# AE302F80F5582LE_CM55_HP_View register map
Vendor: Alif Semiconductor; Series: E3; File version: 1.0
CPU: CM55 r1p0, selectable endian, MPU, FPU, double-precision FPU, DSP, VTOR, 8 interrupt priority bits, 1 SAU regions
Registers are 32-bit, read-write, reset 0x0 unless marked. A register's access mark holds for its fields unless they carry their own. Offsets are from the block's base; [hi:lo] are bit positions; {n}, {i} and the like mark numbered series; 'fields as' and 'values as' point back to an identical list.

## DSI
Base 0x49032000
0x00 DSI_VERSION ro reset 0x3134312A — DSI Host Controller Version Register
  [31:0] VERSION — Module version
0x04 DSI_PWR_UP — Power-up Control Register
  [0] SHUTDOWNZ — This bit configures the controller either to power up or to reset.
    0=Reset the controller; 1=Power up the controller
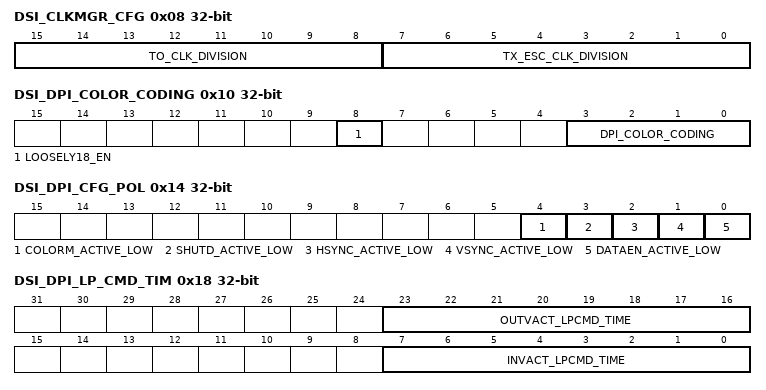
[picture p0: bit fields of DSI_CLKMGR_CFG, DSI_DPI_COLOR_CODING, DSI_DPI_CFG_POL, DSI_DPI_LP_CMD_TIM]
0x08 DSI_CLKMGR_CFG — Clock Control Register
  [15:8] TO_CLK_DIVISION — This field indicates the division factor for the Timeout clock used as the timing unit in the configuration of high-speed to low-power and low-power to high-speed transition error.
  [7:0] TX_ESC_CLK_DIVISION — This field indicates the division factor for the TX Escape clock source (LANEBYTECLK). The values 0 and 1 stop the TXCLKESC generation.
0x0C DSI_DPI_VCID — VC ID Configuration Register
  [1:0] DPI_VCID — This field configures the DPI Virtual Channel ID that is indexed to the Video mode packets.
0x10 DSI_DPI_COLOR_CODING — DPI Color Coding Register
  [8] LOOSELY18_EN — When set to 1, this bit activates loosely packed variant to 18-bit configurations.
  [3:0] DPI_COLOR_CODING — This field configures the DPI color for Video mode coding as follows:
    1=16-bit configuration 2; 4=18-bit configuration 2; 5=24-bit
0x14 DSI_DPI_CFG_POL — DPI Polarity Configuration Register
  [4] COLORM_ACTIVE_LOW — When set to 1, this bit configures the color mode pin (DPICOLORM) as active-low.
  [3] SHUTD_ACTIVE_LOW — When set to 1, this bit configures the shutdown pin (DPISHUTDN) as active-low.
  [2] HSYNC_ACTIVE_LOW — When set to 1, this bit configures the horizontal synchronism pin (DPIHSYNC) as active-low.
  [1] VSYNC_ACTIVE_LOW — When set to 1, this bit configures the vertical synchronism pin (DPIVSYNC) as active-low.
  [0] DATAEN_ACTIVE_LOW — When set to 1, this bit configures the data enable pin (DPIDATAEN) as active-low.
0x18 DSI_DPI_LP_CMD_TIM — DPI Low-Power Mode Configuration Register
  [23:16] OUTVACT_LPCMD_TIME — This field is used for the transmission of commands in low-power mode. It defines the size, in bytes, of the largest packet that can fit in a line during the VSA, VBP, and VFP regions.
  [7:0] INVACT_LPCMD_TIME — This field is used for the transmission of commands in low-power mode. It defines the size, in bytes, of the largest packet that can fit in a line during the VACT region.
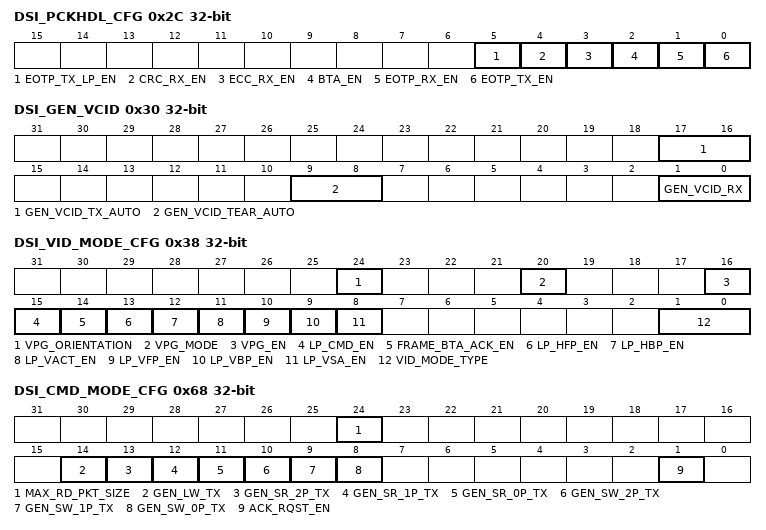
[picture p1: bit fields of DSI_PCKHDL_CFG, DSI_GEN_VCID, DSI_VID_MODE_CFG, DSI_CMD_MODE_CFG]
0x2C DSI_PCKHDL_CFG — Protocol Configuration Register
  [5] EOTP_TX_LP_EN — When set to 1, this bit enables the EoTp transmission in low-power.
  [4] CRC_RX_EN — When set to 1, this bit enables the CRC reception and error reporting.
  [3] ECC_RX_EN — When set to 1, this bit enables the ECC reception, error correction, and reporting.
  [2] BTA_EN — When set to 1, this bit enables the Bus Turn-Around (BTA) request.
  [1] EOTP_RX_EN — When set to 1, this bit enables the EoTp reception.
  [0] EOTP_TX_EN — When set to 1, this bit enables the EoTp transmission in high-speed.
0x30 DSI_GEN_VCID — Generic VC ID Configuration Register
  [17:16] GEN_VCID_TX_AUTO — This field indicates the Generic interface virtual channel identification where generic packet is automatically generated and transmitted.
  [9:8] GEN_VCID_TEAR_AUTO — This field indicates the virtual channel identification for tear effect by hardware
  [1:0] GEN_VCID_RX — This field indicates the Generic interface read-back virtual channel identification.
0x34 DSI_MODE_CFG reset 0x1 — Mode Configuration Register
  [0] CMD_VIDEO_MODE — This bit configures the operation mode:
    0=Video mode; 1=Command mode. Not supported by the DSI controller in this device.
0x38 DSI_VID_MODE_CFG — Video Mode Configuration Register
  [24] VPG_ORIENTATION — This field indicates the color bar orientation as follows:
    0=Vertical mode; 1=Horizontal mode
  [20] VPG_MODE — This field is to select the pattern:
    0=Horizontal or vertical; 1=Vertical only
  [16] VPG_EN — When set to 1, this bit enables the video mode pattern generator.
  [15] LP_CMD_EN — When set to 1, this bit enables the command transmission only in low-power mode.
  [14] FRAME_BTA_ACK_EN — When set to 1, this bit enables the request for an acknowledge response at the end of a frame.
  [13] LP_HFP_EN — When set to 1, this bit enables the return to low-power inside the HFP period when timing allows.
  [12] LP_HBP_EN — When set to 1, this bit enables the return to low-power inside the HBP period when timing allows.
  [11] LP_VACT_EN — When set to 1, this bit enables the return to low-power inside the VACT period when timing allows.
  [10] LP_VFP_EN — When set to 1, this bit enables the return to low-power inside the VFP period when timing allows.
  [9] LP_VBP_EN — When set to 1, this bit enables the return to low-power inside the VBP period when timing allows.
  [8] LP_VSA_EN — When set to 1, this bit enables the return to low-power inside the VSA period when timing allows.
  [1:0] VID_MODE_TYPE — This field indicates the video mode transmission type as follows:
    0=Non-Burst with sync pulses; 1=Non-Burst with sync events; 2=Burst mode; 3=Burst mode
0x3C DSI_VID_PKT_SIZE — Video Packet Size Register
  [13:0] VID_PKT_SIZE — This field configures the number of pixels in a single video packet.
0x40 DSI_VID_NUM_CHUNKS — Video Chunks Configuration Register
  [12:0] VID_NUM_CHUNKS — This register configures the number of chunks to be transmitted during a Line period (a chunk is pair made of a video packet and a null packet). If set to 0 or 1, video line is still transmitted in a single packet. If set to 1 that packet is part of a chunk, meaning that a null packet follows it (if DSI_VID_NULL_SIZE > 0). Otherwise, multiple chunks are used to transmit each video line.
0x44 DSI_VID_NULL_SIZE — Video Null Packet Configuration Register
  [12:0] VID_NULL_SIZE — This register configures the number of bytes inside a null packet. Setting to 0 disables null packets.
0x48 DSI_VID_HSA_TIME — Video HSA Configuration Register
  [11:0] VID_HSA_TIME — This field configures the Horizontal Synchronism Active period in LANEBYTECLK cycles.
0x4C DSI_VID_HBP_TIME — Video HBP Configuration Register
  [11:0] VID_HBP_TIME — This field configures the HBP period in LANEBYTECLK cycles.
0x50 DSI_VID_HLINE_TIME — Video Line Configuration Register
  [14:0] VID_HLINE_TIME — This field configures the size of the total line time (HSA + HBP + HACT + HFP) counted in LANEBYTECLK cycles.
0x54 DSI_VID_VSA_LINES — Video VSA Configuration Register
  [9:0] VSA_LINES — This field configures the VSA period measured in number of horizontal lines.
0x58 DSI_VID_VBP_LINES — Video VBP Configuration Register
  [9:0] VBP_LINES — This field configures the VBP period measured in number of horizontal lines.
0x5C DSI_VID_VFP_LINES — Video VFP Configuration Register
  [9:0] VFP_LINES — This field configures the VFP period measured in number of horizontal lines.
0x60 DSI_VID_VACTIVE_LINES — Video VA Configuration Register
  [13:0] V_ACTIVE_LINES — This field configures the VA period measured in number of horizontal lines.
0x68 DSI_CMD_MODE_CFG — Generic Packet Command Configuration Register
  [24] MAX_RD_PKT_SIZE — This bit configures the maximum read packet size command transmission type:
    0=Transition type is high-speed; 1=Transition type is low-power
  [14] GEN_LW_TX — This bit configures the Generic long write packet command transmission type:
    values as MAX_RD_PKT_SIZE
  [13] GEN_SR_2P_TX — This bit configures the Generic short read packet with two parameters command transmission type:
    values as MAX_RD_PKT_SIZE
  [12] GEN_SR_1P_TX — This bit configures the Generic short read packet with one parameter command transmission type:
    values as MAX_RD_PKT_SIZE
  [11] GEN_SR_0P_TX — This bit configures the Generic short read packet with zero parameter command transmission type:
    values as MAX_RD_PKT_SIZE
  [10] GEN_SW_2P_TX — This bit configures the Generic short write packet with two parameters command transmission type:
    values as MAX_RD_PKT_SIZE
  [9] GEN_SW_1P_TX — This bit configures the Generic short write packet with one parameter command transmission type:
    values as MAX_RD_PKT_SIZE
  [8] GEN_SW_0P_TX — This bit configures the Generic short write packet with zero parameter command transmission type:
    values as MAX_RD_PKT_SIZE
  [1] ACK_RQST_EN — When set to 1, this bit enables the acknowledge request after each packet transmission.
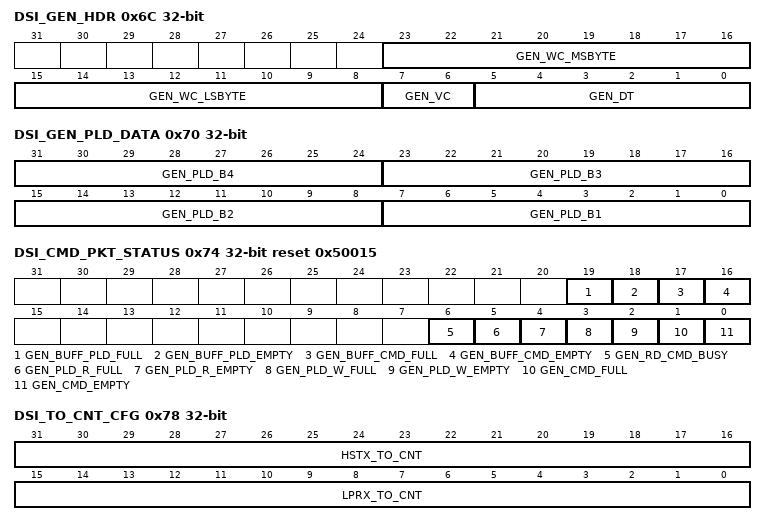
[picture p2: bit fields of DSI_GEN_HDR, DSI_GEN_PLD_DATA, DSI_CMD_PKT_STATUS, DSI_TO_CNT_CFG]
0x6C DSI_GEN_HDR — Generic Header Configuration Register
  [23:16] GEN_WC_MSBYTE — This field configures the most significant byte of the header packet's word count for long packets or data 1 for short packets.
  [15:8] GEN_WC_LSBYTE — This field configures the least significant byte of the header packet's Word count for long packets or data 0 for short packets.
  [7:6] GEN_VC — This field configures the Virtual Channel ID of the header packet.
  [5:0] GEN_DT — This field configures the packet Data Type of the header packet.
0x70 DSI_GEN_PLD_DATA — Generic Payload Data Register
  [8n-1:8n-8] GEN_PLD_B{n} (n=1..4) — This field indicates byte {n} of the packet payload.
0x74 DSI_CMD_PKT_STATUS ro reset 0x50015 — Generic Packet Status Register
  [19] GEN_BUFF_PLD_FULL — This bit indicates the full status of the generic payload internal buffer.
  [18] GEN_BUFF_PLD_EMPTY — This bit indicates the empty status of the generic payload internal buffer.
  [17] GEN_BUFF_CMD_FULL — This bit indicates the full status of the generic command internal buffer.
  [16] GEN_BUFF_CMD_EMPTY — This bit indicates the empty status of the generic command internal buffer.
  [6] GEN_RD_CMD_BUSY — This bit is set when a read command is issued and cleared when the entire response is stored in the FIFO for Generic interface.
  [5] GEN_PLD_R_FULL — This bit indicates the full status of the generic read payload FIFO.
  [4] GEN_PLD_R_EMPTY — This bit indicates the empty status of the generic read payload FIFO.
  [3] GEN_PLD_W_FULL — This bit indicates the full status of the generic write payload FIFO.
  [2] GEN_PLD_W_EMPTY — This bit indicates the empty status of the generic write payload FIFO.
  [1] GEN_CMD_FULL — This bit indicates the full status of the generic command FIFO.
  [0] GEN_CMD_EMPTY — This bit indicates the empty status of the generic command FIFO.
0x78 DSI_TO_CNT_CFG — Timeout Counter Configuration Register
  [31:16] HSTX_TO_CNT — This field configures the timeout counter that triggers a high-speed transmission timeout contention detection (measured in DSI_CLKMGR_CFG[TO_CLK_DIVISION] cycles). If using non-burst mode and there is not sufficient time to switch from high-speed to low-power and back in the period which is from one line data finishing to the next line sync start, the DSI link returns low-power state once per frame, then the DSI_CLKMGR_CFG[TO_CLK_DIVISION] and HSTX_TO_CNT fields should be configured to satisfy the following formula: HSTX_TO_CNT x LANEBYTECLK_period x TO_CLK_DIVISION >= the time of one FRAME data transmission x (1 + 10%) In burst mode, RGB pixel packets are time-compressed, leaving more time during a scan line. So if in burst mode and there is sufficient time to switch from high-speed to low-power and back in the period of time from one line data finishing to the next line sync start, the DSI link can return low-power mode and back in this time interval to save power. If this case, the DSI_CLKMGR_CFG[TO_CLK_DIVISION] and HSTX_TO_CNT fields should be configured to satisfy the following formula: HSTX_TO_CNT x LANEBYTECLK_period x TO_CLK_DIVISION >= the time of one LINE data transmission x (1 + 10%)
  [15:0] LPRX_TO_CNT — This field configures the timeout counter that triggers a low-power reception timeout contention detection (measured in DSI_CLKMGR_CFG[TO_CLK_DIVISION] cycles).
0x7C DSI_HS_RD_TO_CNT — HS Read Timeout Configuration Register
  [15:0] HS_RD_TO_CNT — This field sets a period for which DSI controller keeps the link still, after sending a high-speed Read operation. This period is measured in cycles of LANEBYTECLK, starts to count when the D-PHY enters stop state and causes no interrupts.
0x80 DSI_LP_RD_TO_CNT — LP Read Timeout Configuration Register
  [15:0] LP_RD_TO_CNT — This field sets a period for which DSI controller keeps the link still, after sending a low-power Read operation. This period is measured in cycles of LANEBYTECLK, starts to count when the D-PHY enters stop state and causes no interrupts.
0x84 DSI_HS_WR_TO_CNT — HS Write Timeout Configuration Register
  [15:0] HS_WR_TO_CNT — This field sets a period for which DSI controller keeps the link still, after sending a high-speed Write operation. This period is measured in cycles of LANEBYTECLK, starts to count when the D-PHY enters stop state and causes no interrupts.
0x88 DSI_LP_WR_TO_CNT — LP Write Timeout Configuration Register
  [15:0] LP_WR_TO_CNT — This field sets a period for which DSI controller keeps the link still, after sending a low-power Write operation. This period is measured in cycles of LANEBYTECLK, starts to count when the D-PHY enters stop state and causes no interrupts.
0x8C DSI_BTA_TO_CNT — BTA Timeout Configuration Register
  [15:0] BTA_TO_CNT — This field sets a period for which DSI controller keeps the link still, after completing a BTA. This period is measured in cycles of LANEBYTECLK, starts to count when the D-PHY enters Stop state and causes no interrupts.
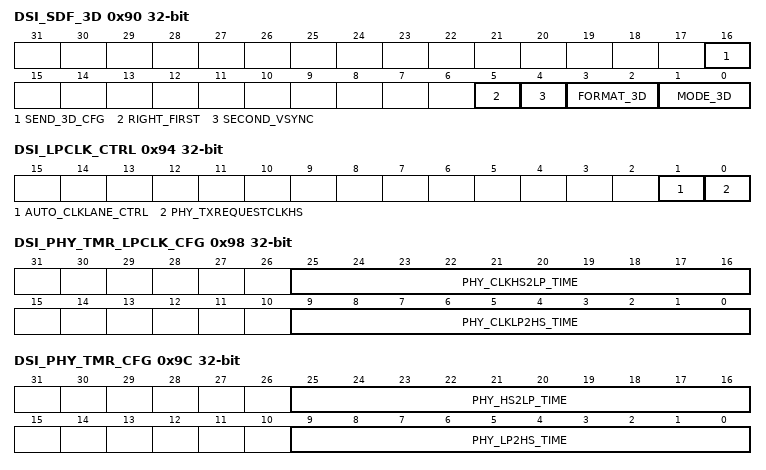
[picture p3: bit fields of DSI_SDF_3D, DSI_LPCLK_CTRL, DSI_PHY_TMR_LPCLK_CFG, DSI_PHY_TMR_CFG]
0x90 DSI_SDF_3D — 3D Control Register
  [16] SEND_3D_CFG — When set, causes the next VSS packet to include 3D control payload in every VSS packet.
  [5] RIGHT_FIRST — This bit defines the left/right order:
    0=Left eye is sent first, then right eye; 1=Right eye data is sent first, then left eye
  [4] SECOND_VSYNC — This field defines whether there is a second VSYNC pulse between Left and Right Images, when 3D Image Format is Frame-based:
    0=No sync pulses between left and right data; 1=Sync pulse HSYNC, VSYNC, blanking between left and right data
  [3:2] FORMAT_3D — This field defines 3D Image Format:
    0=Alternating lines of left and right data; 1=Alternating frames of left and right data; 2=Alternating pixels of left and right data
  [1:0] MODE_3D — This field defines 3D Mode On/Off and Display Orientation:
    0=3D Mode Off , 2D Mode On; 1=3D Mode On, Portrait Orientation; 2=3D Mode On, Landscape Orientation
0x94 DSI_LPCLK_CTRL — Clock Lane Power Control Register
  [1] AUTO_CLKLANE_CTRL — This bit enables the automatic mechanism to stop providing clock in the clock lane when time allows.
  [0] PHY_TXREQUESTCLKHS — This bit controls the D-PHY PPI TXREQUESTCLKHS signal.
0x98 DSI_PHY_TMR_LPCLK_CFG — Clock Lane Timer Configuration Register
  [25:16] PHY_CLKHS2LP_TIME — This field configures the maximum time that the D-PHY clock lane takes to go from high-speed to low-power transmission measured in LANEBYTECLK cycles.
  [9:0] PHY_CLKLP2HS_TIME — This field configures the maximum time that the D-PHY clock lane takes to go from low-power to high-speed transmission measured in LANEBYTECLK cycles.
0x9C DSI_PHY_TMR_CFG — Data Lane Timer Configuration Register
  [25:16] PHY_HS2LP_TIME — This field configures the maximum time that the D-PHY data lanes take to go from high-speed to low-power transmission measured in LANEBYTECLK cycles.
  [9:0] PHY_LP2HS_TIME — This field configures the maximum time that the D-PHY data lanes take to go from low-power to high-speed transmission measured in LANEBYTECLK cycles.
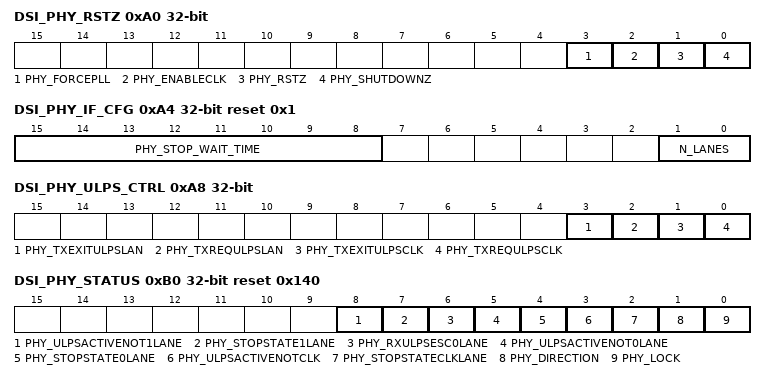
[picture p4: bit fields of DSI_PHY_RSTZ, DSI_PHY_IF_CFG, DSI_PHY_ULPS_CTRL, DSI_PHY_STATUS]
0xA0 DSI_PHY_RSTZ — PHY Control Register
  [3] PHY_FORCEPLL — When the D-PHY is in ULPS, this bit enables the D-PHY PLL.
  [2] PHY_ENABLECLK — When set to 1, this bit enables the D-PHY Clock Lane module.
  [1] PHY_RSTZ — When set to 0, this bit places the digital section of the D-PHY in the reset state.
  [0] PHY_SHUTDOWNZ — When set to 0, this bit places the all D-PHY sub-blocks in power-down state.
0xA4 DSI_PHY_IF_CFG reset 0x1 — PHY Configuration Register
  [15:8] PHY_STOP_WAIT_TIME — This field configures the minimum time PHY needs to stay in Stop state before requesting an high-speed transmission.
  [1:0] N_LANES — This field configures the number of active data lanes:
    0=Data lane 0; 1=Data lanes 0 and 1
0xA8 DSI_PHY_ULPS_CTRL — PHY ULPS Control Register
  [3] PHY_TXEXITULPSLAN — ULPS mode Exit on all active data lanes.
  [2] PHY_TXREQULPSLAN — ULPS mode Request on all active data lanes.
  [1] PHY_TXEXITULPSCLK — ULPS mode Exit on clock lane.
  [0] PHY_TXREQULPSCLK — ULPS mode Request on clock lane.
0xAC DSI_PHY_TX_TRIGGERS — PHY TX Trigger Configuration Register
  [3:0] PHY_TX_TRIGGERS — This field controls the trigger transmissions.
0xB0 DSI_PHY_STATUS ro reset 0x140 — PHY Status Register
  [8] PHY_ULPSACTIVENOT1LANE — This bit indicates the status of ULPSACTIVENOT1LANE D-PHY signal.
  [7] PHY_STOPSTATE1LANE — This bit indicates the status of PHYSTOPSTATE1LANE D-PHY signal.
  [6] PHY_RXULPSESC0LANE — This bit indicates the status of RXULPSESC0LANE D-PHY signal.
  [5] PHY_ULPSACTIVENOT0LANE — This bit indicates the status of ULPSACTIVENOT0LANE D-PHY signal.
  [4] PHY_STOPSTATE0LANE — This bit indicates the status of PHYSTOPSTATE0LANE D-PHY signal.
  [3] PHY_ULPSACTIVENOTCLK — This bit indicates the status of PHYULPSACTIVENOTCLK D-PHY signal.
  [2] PHY_STOPSTATECLKLANE — This bit indicates the status of PHYSTOPSTATECLKLANE D-PHY signal.
  [1] PHY_DIRECTION — This bit indicates the status of PHYDIRECTION D-PHY signal.
  [0] PHY_LOCK — This bit indicates the status of PHYLOCK D-PHY signal.
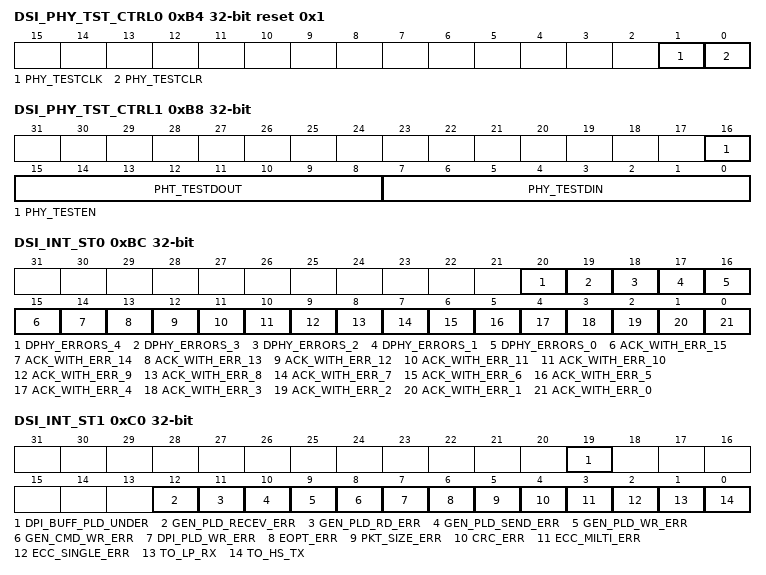
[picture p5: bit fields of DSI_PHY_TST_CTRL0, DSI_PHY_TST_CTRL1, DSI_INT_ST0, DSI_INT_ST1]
0xB4 DSI_PHY_TST_CTRL0 reset 0x1 — PHY Test Interface Control Register 0
  [1] PHY_TESTCLK — This bit is used to clock the TESTDIN bus into the D-PHY.
  [0] PHY_TESTCLR — PHY test interface clear (active-high).
0xB8 DSI_PHY_TST_CTRL1 — PHY Test Interface Control Register 1
  [16] PHY_TESTEN — PHY test interface operation selector:
    0=The data write operation is set on the rising edge of the TESTCLK signal; 1=The address write operation is set on the falling edge of the TESTCLK signal
  [15:8] PHT_TESTDOUT ro — PHY output 8-bit data bus for read-back and internal probing functionalities.
  [7:0] PHY_TESTDIN — PHY test interface input 8-bit data bus for internal register programming and test functionalities access.
0xBC DSI_INT_ST0 ro — Interrupt Status Register 0
  [20] DPHY_ERRORS_4 — This bit indicates LP1 contention error ErrContentionLP1 from Lane 0.
  [19] DPHY_ERRORS_3 — This bit indicates LP0 contention error ErrContentionLP0 from Lane 0.
  [18] DPHY_ERRORS_2 — This bit indicates control error ErrControl from Lane 0.
  [17] DPHY_ERRORS_1 — This bit indicates ErrSyncEsc low-power data transmission synchronization error from Lane 0.
  [16] DPHY_ERRORS_0 — This bit indicates ErrEsc escape entry error from Lane 0.
  [15] ACK_WITH_ERR_15 — This bit retrieves the DSI protocol violation from the Acknowledge error report.
  [14] ACK_WITH_ERR_14 — This bit retrieves the reserved (specific to device) from the Acknowledge error report.
  [13] ACK_WITH_ERR_13 — This bit retrieves the invalid transmission length from the Acknowledge error report.
  [12] ACK_WITH_ERR_12 — This bit retrieves the DSI VC ID Invalid from the Acknowledge error report.
  [11] ACK_WITH_ERR_11 — This bit retrieves the not recognized DSI data type from the Acknowledge error report.
  [10] ACK_WITH_ERR_10 — This bit retrieves the checksum error (long packet only) from the Acknowledge error report.
  [9] ACK_WITH_ERR_9 — This bit retrieves the ECC error, multi-bit (detected, not corrected) from the Acknowledge error report.
  [8] ACK_WITH_ERR_8 — This bit retrieves the ECC error, single-bit (detected and corrected) from the Acknowledge error report.
  [7] ACK_WITH_ERR_7 — This bit retrieves the reserved (specific to device) from the acknowledge error report.
  [6] ACK_WITH_ERR_6 — This bit retrieves the False Control error from the Acknowledge error report.
  [5] ACK_WITH_ERR_5 — This bit retrieves the Peripheral Timeout error from the Acknowledge error report.
  [4] ACK_WITH_ERR_4 — This bit retrieves the low-power Transmit Sync error from the Acknowledge error report.
  [3] ACK_WITH_ERR_3 — This bit retrieves the Escape Mode Entry Command error from the Acknowledge error report.
  [2] ACK_WITH_ERR_2 — This bit retrieves the EoT Sync error from the Acknowledge error report.
  [1] ACK_WITH_ERR_1 — This bit retrieves the SoT Sync error from the Acknowledge error report.
  [0] ACK_WITH_ERR_0 — This bit retrieves the SoT error from the Acknowledge error report.
0xC0 DSI_INT_ST1 ro — Interrupt Status Register 1
  [19] DPI_BUFF_PLD_UNDER — This bit indicates that an underflow has occurred when reading payload to build DSI packet for video mode.
  [12] GEN_PLD_RECEV_ERR — This bit indicates that during a generic interface packet read back, the payload FIFO becomes full and the received data is corrupted.
  [11] GEN_PLD_RD_ERR — This bit indicates that during a DCS read data, the payload FIFO becomes empty and the data sent to the interface is corrupted.
  [10] GEN_PLD_SEND_ERR — This bit indicates that during a Generic interface packet build, the payload FIFO becomes empty and corrupt data is sent.
  [9] GEN_PLD_WR_ERR — This bit indicates that the system tried to write a payload data through the Generic interface and the FIFO is full. Therefore, the payload is not written.
  [8] GEN_CMD_WR_ERR — This bit indicates that the system tried to write a command through the Generic interface and the FIFO is full. Therefore, the command is not written.
  [7] DPI_PLD_WR_ERR — This bit indicates that during a DPI pixel line storage, the payload FIFO becomes full and the data stored is corrupted.
  [6] EOPT_ERR — This bit indicates that the EoTp packet has not been received at the end of the incoming peripheral transmission.
  [5] PKT_SIZE_ERR — This bit indicates that the packet size error has been detected during the packet reception.
  [4] CRC_ERR — This bit indicates that the CRC error has been detected in the received packet payload.
  [3] ECC_MILTI_ERR — This bit indicates that the ECC multiple error has been detected in a received packet.
  [2] ECC_SINGLE_ERR — This bit indicates that the ECC single error has been detected and corrected in a received packet.
  [1] TO_LP_RX — This bit indicates that the low-power reception timeout counter reached the end and contention has been detected.
  [0] TO_HS_TX — This bit indicates that the high-speed transmission timeout counter reached the end and contention has been detected.
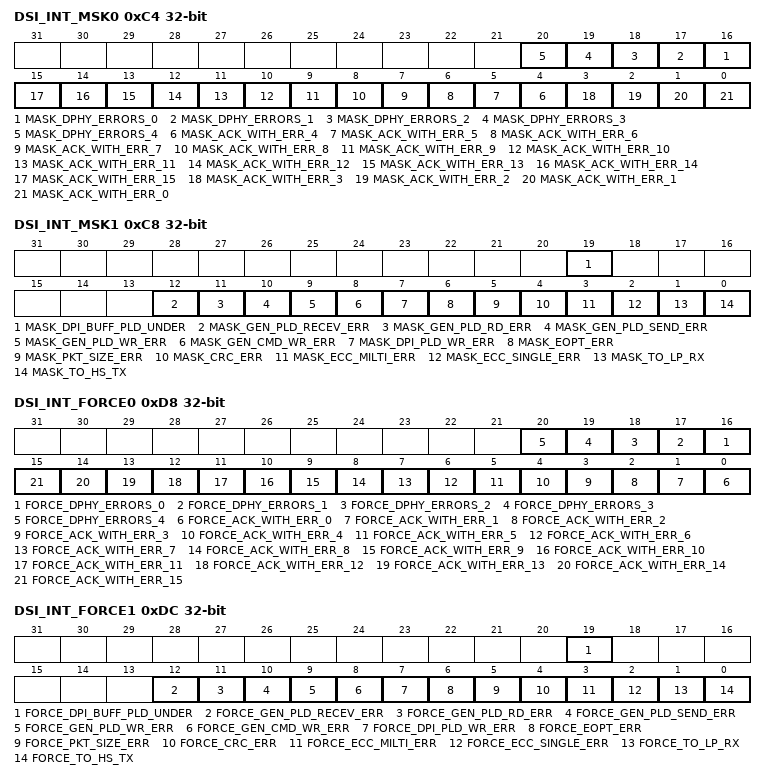
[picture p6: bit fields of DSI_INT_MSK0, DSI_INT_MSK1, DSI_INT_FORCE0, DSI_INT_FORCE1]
0xC4 DSI_INT_MSK0 — Interrupt Mask Register 0
  [n+16] MASK_DPHY_ERRORS_{n} (n=0..4) — Mask for DPHY_ERRORS_{n}.
  [n] MASK_ACK_WITH_ERR_{n} (n=4..15) — Mask for ACK_WITH_ERR_{n}.
  [3] MASK_ACK_WITH_ERR_3 — Mask for ACK_WITH_ERR_3
  [2] MASK_ACK_WITH_ERR_2 — Mask for ACK_WITH_ERR_2
  [1] MASK_ACK_WITH_ERR_1 — Mask for ACK_WITH_ERR_1.
  [0] MASK_ACK_WITH_ERR_0 — Mask for ACK_WITH_ERR_0.
0xC8 DSI_INT_MSK1 — Interrupt Mask Register 1
  [19] MASK_DPI_BUFF_PLD_UNDER — Mask for DPI_BUFF_PLD_UNDER.
  [12] MASK_GEN_PLD_RECEV_ERR — Mask for GEN_PLD_RECEV_ERR.
  [11] MASK_GEN_PLD_RD_ERR — Mask for GEN_PLD_RD_ERR.
  [10] MASK_GEN_PLD_SEND_ERR — Mask for GEN_PLD_SEND_ERR.
  [9] MASK_GEN_PLD_WR_ERR — Mask for GEN_PLD_WR_ERR.
  [8] MASK_GEN_CMD_WR_ERR — Mask for GEN_CMD_WR_ERR.
  [7] MASK_DPI_PLD_WR_ERR — Mask for DPI_PLD_WR_ERR.
  [6] MASK_EOPT_ERR — Mask for EOPT_ERR.
  [5] MASK_PKT_SIZE_ERR — Mask for PKT_SIZE_ERR.
  [4] MASK_CRC_ERR — Mask for CRC_ERR.
  [3] MASK_ECC_MILTI_ERR — Mask for ECC_MILTI_ERR.
  [2] MASK_ECC_SINGLE_ERR — Mask for ECC_SINGLE_ERR.
  [1] MASK_TO_LP_RX — Mask for TO_LP_RX.
  [0] MASK_TO_HS_TX — Mask for TO_HS_TX.
0xCC DSI_PHY_CAL — PHY skew calibration control
  [0] TXSKEWCALHS — High-speed skew calibration is started when this field is set high (assuming that PHY is in Stop state).
0xD8 DSI_INT_FORCE0 — Force Interrupt Register 0
  [n+16] FORCE_DPHY_ERRORS_{n} (n=0..4), [n] FORCE_ACK_WITH_ERR_{n} (n=0..15)
0xDC DSI_INT_FORCE1 — Force Interrupt Register 1
  [19] FORCE_DPI_BUFF_PLD_UNDER — Force for DPI_BUFF_PLD_UNDER.
  [12] FORCE_GEN_PLD_RECEV_ERR
  [11] FORCE_GEN_PLD_RD_ERR
  [10] FORCE_GEN_PLD_SEND_ERR
  [9] FORCE_GEN_PLD_WR_ERR
  [8] FORCE_GEN_CMD_WR_ERR
  [7] FORCE_DPI_PLD_WR_ERR
  [6] FORCE_EOPT_ERR
  [5] FORCE_PKT_SIZE_ERR
  [4] FORCE_CRC_ERR
  [3] FORCE_ECC_MILTI_ERR
  [2] FORCE_ECC_SINGLE_ERR
  [1] FORCE_TO_LP_RX
  [0] FORCE_TO_HS_TX
0xF4 DSI_PHY_TMR_RD_CFG — Data Lane Timer Read Configuration Register
  [14:0] MAX_RD_TIME — This field configures the maximum time required to perform a read command in LANEBYTECLK cycles. This register can only be modified when no read command is in progress.
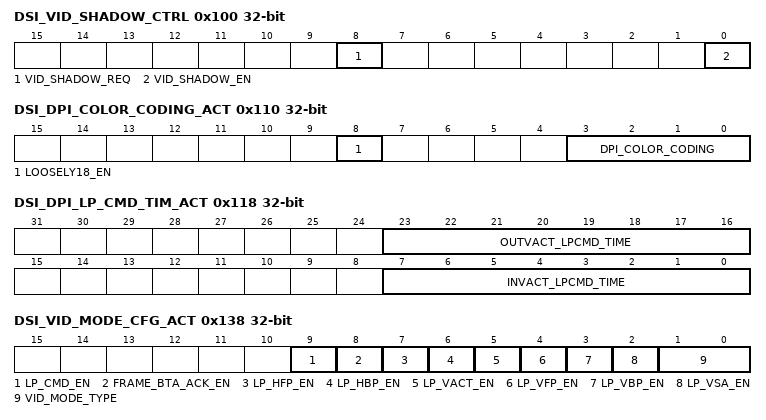
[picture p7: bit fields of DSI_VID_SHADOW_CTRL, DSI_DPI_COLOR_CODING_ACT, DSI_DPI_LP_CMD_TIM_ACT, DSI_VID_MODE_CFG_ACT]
0x100 DSI_VID_SHADOW_CTRL — Video Shadow Control Register
  [8] VID_SHADOW_REQ — When set to 1, this bit requests that the DPI registers are copied to the auxiliary registers. When the request is completed this bit is auto cleared.
  [0] VID_SHADOW_EN — When set to 1, DPI receives the active configuration from the auxiliary registers. When the feature is set at the same time than VID_SHADOW_REQ the auxiliary registers are automatically updated.
0x10C DSI_DPI_VCID_ACT ro — Current VC ID Register
  [1:0] DPI_VCID — This field specifies the DPI Virtual Channel ID that is indexed to the Video mode packets.
0x110 DSI_DPI_COLOR_CODING_ACT ro — Current Color Coding Register
  [8] LOOSELY18_EN — When 1, this bit activates loosely packed variant to 18-bit configurations.
  [3:0] DPI_COLOR_CODING — This field configures the DPI color for Video Mode/eDPI Command Mode coding as follows:
    1=16-bit configuration 2; 4=18-bit configuration 2; 5=24-bit
0x118 DSI_DPI_LP_CMD_TIM_ACT ro — Low-Power Mode Current Configuration Register
  [23:16] OUTVACT_LPCMD_TIME — This field is used for the transmission of commands in low-power mode. It specifies the size, in bytes, of the largest packet that can fit in a line during the VSA, VBP, and VFP regions.
  [7:0] INVACT_LPCMD_TIME — This field is used for the transmission of commands in low-power mode. It specifies the size, in bytes, of the largest packet that can fit in a line during the VACT region.
0x138 DSI_VID_MODE_CFG_ACT ro — Video Mode Current Configuration Register
  [9] LP_CMD_EN — When 1, this bit enables the command transmission only in low-power mode.
  [8] FRAME_BTA_ACK_EN — When 1, this bit enables the request for an acknowledge response at the end of a frame.
  [7] LP_HFP_EN — When 1, this bit enables the return to low-power inside the HFP period when timing allows.
  [6] LP_HBP_EN — When 1, this bit enables the return to low-power inside the HBP period when timing allows.
  [5] LP_VACT_EN — When 1, this bit enables the return to low-power inside the VACT period when timing allows.
  [4] LP_VFP_EN — When 1, this bit enables the return to low-power inside the VFP period when timing allows.
  [3] LP_VBP_EN — When 1, this bit enables the return to low-power inside the VBP period when timing allows.
  [2] LP_VSA_EN — When 1, this bit enables the return to low-power inside the VSA period when timing allows.
  [1:0] VID_MODE_TYPE — This field specifies the Video mode transmission type as follows:
    values as DSI_VID_MODE_CFG.VID_MODE_TYPE
0x13C DSI_VID_PKT_SIZE_ACT ro — Video Packet Size Current Configuration Register
  [13:0] VID_PKT_SIZE — This field specifies the number of pixels in a single video packet.
0x140 DSI_VID_NUM_CHUNKS_ACT ro — Video Chunks Current Configuration Register
  [12:0] VID_NUM_CHUNKS — This register specifies the number of chunks to be transmitted during a Line period (a chunk is pair made of a video packet and a null packet). If set to 0 or 1, video line is still transmitted in a single packet. If set to 1 that packet is part of a chunk, meaning that a null packet follows it (if DSI_VID_NULL_SIZE > 0). Otherwise, multiple chunks are used to transmit each video line.
0x144 DSI_VID_NULL_SIZE_ACT ro — Video Null Packet Size Current Configuration Register
  [12:0] VID_NULL_SIZE — This register specifies the number of bytes inside a null packet. Setting to 0 disables null packets.
0x148 DSI_VID_HSA_TIME_ACT ro — Video HSA Current Configuration Register
  [11:0] VID_HSA_TIME — This field specifies the HSA period in LANEBYTECLK cycles.
0x14C DSI_VID_HBP_TIME_ACT ro — Video HBP Current Configuration Register
  [11:0] VID_HBP_TIME — This field specifies the HBP period in LANEBYTECLK cycles.
0x150 DSI_VID_HLINE_TIME_ACT ro — Video Line Current Configuration Register
  [14:0] VID_HLINE_TIME — This field specifies the size of the total line time (HSA + HBP + HACT + HFP) counted in LANEBYTECLK cycles.
0x154 DSI_VID_VSA_LINES_ACT ro — Video VSA Current Configuration Register
  [9:0] VSA_LINES — This field specifies the VSA period measured in number of horizontal lines.
0x158 DSI_VID_VBP_LINES_ACT ro — Video VBP Current Configuration Register
  [9:0] VBP_LINES — This field specifies the VBP period measured in number of horizontal lines.
0x15C DSI_VID_VFP_LINES_ACT ro — Video VFP Current Configuration Register
  [9:0] VFP_LINES — This field specifies the VFP period measured in number of horizontal lines.
0x160 DSI_VID_VACTIVE_LINES_ACT ro — Video VA Current Configuration Register
  [13:0] V_ACTIVE_LINES — This field specifies the VA period measured in number of horizontal lines.
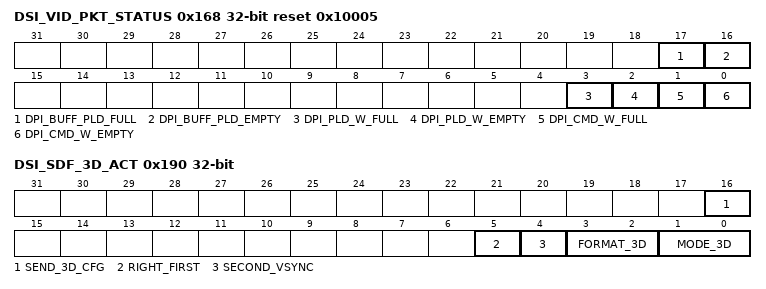
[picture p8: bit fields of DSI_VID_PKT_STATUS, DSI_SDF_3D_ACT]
0x168 DSI_VID_PKT_STATUS ro reset 0x10005 — Video Packet Status Register
  [17] DPI_BUFF_PLD_FULL — This bit indicates the full status of the payload internal buffer for Video mode. This bit is set to 0 for Command mode.
  [16] DPI_BUFF_PLD_EMPTY — This bit indicates the empty status of the payload internal buffer for Video mode. This bit is set to 0 for Command mode.
  [3] DPI_PLD_W_FULL — This bit indicates the full status of write payload FIFO for Video mode. This bit is set to 0 for Command mode.
  [2] DPI_PLD_W_EMPTY — This bit indicates the empty status of write payload FIFO for Video mode. This bit is set to 0 for Command mode.
  [1] DPI_CMD_W_FULL — This bit indicates the full status of write command FIFO for Video mode. This bit is set to 0 for Command mode.
  [0] DPI_CMD_W_EMPTY — This bit indicates the empty status of write command FIFO for Video mode. This bit is set to 0 for Command mode.
0x190 DSI_SDF_3D_ACT ro — 3D Current Configuration Register
  [16] SEND_3D_CFG — When set, causes the next VSS packet to include 3D control payload in every VSS packet.
  [5] RIGHT_FIRST — This bit specifies the left/right order:
    values as DSI_SDF_3D.RIGHT_FIRST
  [4] SECOND_VSYNC — This field specifies whether there is a second VSYNC pulse between Left and Right Images, when 3D Image Format is Frame-based:
    0=No sync pulses between left and right data; 1=Sync pulse (HSYNC, VSYNC, blanking) between left and right data
  [3:2] FORMAT_3D — This field specifies 3D Image Format:
    values as DSI_SDF_3D.FORMAT_3D
  [1:0] MODE_3D — This field specifies 3D Mode On/Off and Display Orientation:
    0=3D Mode Off, 2D Mode On; 1=3D Mode On, Portrait Orientation; 2=3D Mode On, Landscape Orientation
